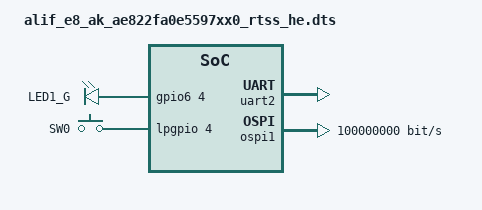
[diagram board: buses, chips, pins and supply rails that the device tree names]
/* Copyright (c) 2025 Alif Semiconductor
 *
 * SPDX-License-Identifier: Apache-2.0
 */

/dts-v1/;

#include <alif/ensemble/common/e8_appkit.dtsi>
#include <alif/ensemble/common/ensemble_rtss_he.dtsi>
#include "../common/ensemble-e8-appkit-pinctrl.dtsi"
#include "../common/alif-sd-vsel.dtsi"

/ {
	compatible = "arm,alif-e8-ak-ae822fa0e5597xx0-rtss-he";
	#address-cells = <1>;
	#size-cells = <1>;

	chosen {
		zephyr,flash = &mram_storage;
		zephyr,code-partition = &slot0_partition;
		zephyr,sram = &dtcm;
		zephyr,console = &uart2;
		zephyr,shell-uart = &uart2;
		zephyr,uart-mcumgr = &uart2;
	};

	aliases {
		led0 = &aled0;
		sw0 = &button0;
		watchdog0 = &wdog0;
	};

	leds {
		compatible = "gpio-leds";
		aled0: led_0 {
			gpios = <&gpio6 4 0>;
			label = "LED1_G";
		};
	};
	buttons {
		compatible = "gpio-keys";
		button0: button_0 {
			gpios = <&lpgpio 4 0>;
			label = "SW0";
		};
	};
};

&gpio6 {
	status = "okay";
};

&lpgpio {
	status = "okay";
};

&uart2 {
	status = "okay";
};

&ospi0 {
	aps512xxn: aps512xxn@0 {
		compatible = "alif,apmemory-aps512xxn";
		reg = <0>;
		size = <DT_SIZE_M(64)>;
		x16-data-transfer-mode;
		latency-code = <4>;
		status = "disabled";
	};
};

&ospi1 {
	compatible = "snps,designware-ospi";
	reg = <0x83002000 0x1000>,
	      <0xC0000000 0x20000000>,
	      <0x83003000 0x100>;
	reg-names = "core", "xip", "aes";
	/delete-property/ packet-data-limit;
	/delete-property/ fifo-depth;
	/delete-property/ op-mode;
	/delete-property/ rx-fifo-threshold;
	aes-reg = <0x83003000 0x100>;
	bus-speed = <100000000>;
	cs-pin = <0>;
	xip-base-address = <0xC0000000 0x20000000>;

	/* External Flash on OSPI */
	ospi_flash: ospi_flash@0 {
		compatible = "mxicy,mx66uw-flash";
		reg = <0x0>;
		erase-value = <0xff>;
		num-of-sector = <32768>;
		page-size = <4096>;
		sector-size = <4096>;
		write-block-size = <2>;

		/* Flash Size 128MB */
		#address-cells = <1>;
		#size-cells = <1>;

		/* wait cycles based on bus speed*/
		def-wait-cycle = <5>;
		read-wait-cycle = <10>;

		flash_storage: flash_storage@0 {
			compatible = "soc-nv-flash";
			reg = <0x0 DT_SIZE_M(128)>;
			erase-block-size = <DT_SIZE_K(4)>;
			write-block-size = <2>;
		};
		status = "disabled";
	};
};
